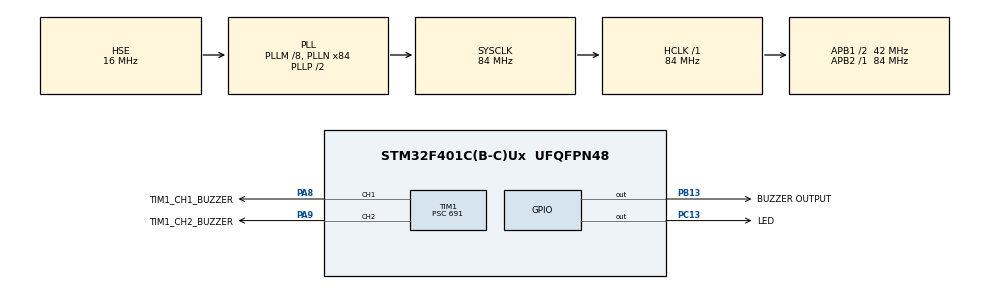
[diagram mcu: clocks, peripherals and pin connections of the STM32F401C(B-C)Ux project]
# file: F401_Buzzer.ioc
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Mcu.Family=STM32F4
Mcu.Name=STM32F401C(B-C)Ux
Mcu.Package=UFQFPN48
NVIC.PriorityGroup=NVIC_PRIORITYGROUP_4
PA13.Mode=Serial_Wire
PA13.Signal=SYS_JTMS-SWDIO
PA14.Mode=Serial_Wire
PA14.Signal=SYS_JTCK-SWCLK
PA8.GPIO_Label=TIM1_CH1_BUZZER
PA8.Signal=S_TIM1_CH1
PA9.GPIO_Label=TIM1_CH2_BUZZER
PA9.Signal=S_TIM1_CH2
PB13.GPIO_Label=BUZZER OUTPUT
PB13.Signal=GPIO_Output
PC13-ANTI_TAMP.GPIO_Label=LED
PC13-ANTI_TAMP.Signal=GPIO_Output
PH0\ -\ OSC_IN.Mode=HSE-External-Oscillator
PH0\ -\ OSC_IN.Signal=RCC_OSC_IN
PH1\ -\ OSC_OUT.Mode=HSE-External-Oscillator
PH1\ -\ OSC_OUT.Signal=RCC_OSC_OUT
ProjectManager.HeapSize=0x200
ProjectManager.StackSize=0x400
ProjectManager.TargetToolchain=STM32CubeIDE
RCC.48MHZClocksFreq_Value=42000000
RCC.AHBFreq_Value=84000000
RCC.APB1CLKDivider=RCC_HCLK_DIV2
RCC.APB1Freq_Value=42000000
RCC.APB1TimFreq_Value=84000000
RCC.APB2Freq_Value=84000000
RCC.APB2TimFreq_Value=84000000
RCC.CortexFreq_Value=84000000
RCC.HCLKFreq_Value=84000000
RCC.HSE_VALUE=16000000
RCC.HSI_VALUE=16000000
RCC.LSE_VALUE=32768
RCC.PLLM=8
RCC.PLLN=84
RCC.PLLSourceVirtual=RCC_PLLSOURCE_HSE
RCC.SYSCLKFreq_VALUE=84000000
RCC.SYSCLKSource=RCC_SYSCLKSOURCE_PLLCLK
RCC.VCOOutputFreq_Value=168000000
SH.S_TIM1_CH1.0=TIM1_CH1,PWM Generation1 CH1
SH.S_TIM1_CH2.0=TIM1_CH2,PWM Generation2 CH2
TIM1.Channel-PWM\ Generation1\ CH1=TIM_CHANNEL_1
TIM1.Channel-PWM\ Generation2\ CH2=TIM_CHANNEL_2
TIM1.Period=999
TIM1.Prescaler=691
VP_TIM1_VS_ClockSourceINT.Mode=Internal
board=custom

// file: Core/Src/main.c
/* USER CODE BEGIN Header */
/**
  ******************************************************************************
  * @file           : main.c
  * @brief          : Main program body
  ******************************************************************************
  * @attention
  *
  * Copyright (c) 2024 STMicroelectronics.
  * All rights reserved.
  *
  * This software is licensed under terms that can be found in the LICENSE file
  * in the root directory of this software component.
  * If no LICENSE file comes with this software, it is provided AS-IS.
  *
  ******************************************************************************
  */
/* USER CODE END Header */
#include "main.h"
#include "tim.h"
#include "gpio.h"

void SystemClock_Config(void);

int main(void)
{

  /* MCU Configuration--------------------------------------------------------*/

  /* Reset of all peripherals, Initializes the Flash interface and the Systick. */
  HAL_Init();

  /* Configure the system clock */
  SystemClock_Config();

  /* Initialize all configured peripherals */
  MX_GPIO_Init();
  MX_TIM1_Init();
  /* USER CODE BEGIN 2 */

	 /* BUZZER TIMER1 CH1 PIN A8 */

  	  	  HAL_TIM_PWM_Start(&htim1, TIM_CHANNEL_1);

  	 /* BUZZER TIMER1 CH2 PIN A9 */

  	  	  HAL_TIM_PWM_Start(&htim1, TIM_CHANNEL_2);

  /* USER CODE END 2 */

  /* Infinite loop */
  while (1)
  {

    /* USER CODE BEGIN 3 */

	    /* BUZZER PIN B13 OUTPUT */

	  	  	/*
				  HAL_GPIO_TogglePin(GPIOB, GPIO_PIN_13);
				  HAL_Delay(500);

	  	  	*/

	 /* BUZZER TIMER1 CH1 PIN A8. Prescaler set to 83, Counter Period 999  */

	  	  /*
			  int x;
			  for(x=10; x<30; x=x+1)
			  {
				__HAL_TIM_SET_AUTORELOAD(&htim1, x*2);
				__HAL_TIM_SET_COMPARE(&htim1,TIM_CHANNEL_1, x);
				HAL_Delay(100);

			  }

		    }

		*/

	  /* BUZZER TIMER1 CH2 PIN A9. Prescaler set to 83, Counter Period 999  */

		  uint8_t value = 0; // the value for the duty cycle
		  while (value<255)
		  {
			htim1.Instance->CCR2 = value; // vary the duty cycle
			value += 20; // increase the duty cycle by 20
			HAL_Delay (500); // wait for 500 ms
		  }
		  value = 0; // reset the value

//		  HAL_GPIO_TogglePin(GPIOC, GPIO_PIN_13);
//		  HAL_Delay(100);

  }

  /* USER CODE END 3 */
}

void SystemClock_Config(void)
{
  RCC_OscInitTypeDef RCC_OscInitStruct = {0};
  RCC_ClkInitTypeDef RCC_ClkInitStruct = {0};

  /** Configure the main internal regulator output voltage
  */
  __HAL_RCC_PWR_CLK_ENABLE();
  __HAL_PWR_VOLTAGESCALING_CONFIG(PWR_REGULATOR_VOLTAGE_SCALE2);

  /** Initializes the RCC Oscillators according to the specified parameters
  * in the RCC_OscInitTypeDef structure.
  */
  RCC_OscInitStruct.OscillatorType = RCC_OSCILLATORTYPE_HSE;
  RCC_OscInitStruct.HSEState = RCC_HSE_ON;
  RCC_OscInitStruct.PLL.PLLState = RCC_PLL_ON;
  RCC_OscInitStruct.PLL.PLLSource = RCC_PLLSOURCE_HSE;
  RCC_OscInitStruct.PLL.PLLM = 8;
  RCC_OscInitStruct.PLL.PLLN = 84;
  RCC_OscInitStruct.PLL.PLLP = RCC_PLLP_DIV2;
  RCC_OscInitStruct.PLL.PLLQ = 4;
  if (HAL_RCC_OscConfig(&RCC_OscInitStruct) != HAL_OK)
  {
    Error_Handler();
  }

  /** Initializes the CPU, AHB and APB buses clocks
  */
  RCC_ClkInitStruct.ClockType = RCC_CLOCKTYPE_HCLK|RCC_CLOCKTYPE_SYSCLK
                              |RCC_CLOCKTYPE_PCLK1|RCC_CLOCKTYPE_PCLK2;
  RCC_ClkInitStruct.SYSCLKSource = RCC_SYSCLKSOURCE_PLLCLK;
  RCC_ClkInitStruct.AHBCLKDivider = RCC_SYSCLK_DIV1;
  RCC_ClkInitStruct.APB1CLKDivider = RCC_HCLK_DIV2;
  RCC_ClkInitStruct.APB2CLKDivider = RCC_HCLK_DIV1;

  if (HAL_RCC_ClockConfig(&RCC_ClkInitStruct, FLASH_LATENCY_2) != HAL_OK)
  {
    Error_Handler();
  }
}

void Error_Handler(void)
{
  __disable_irq();
  while (1)
  {
  }
}
